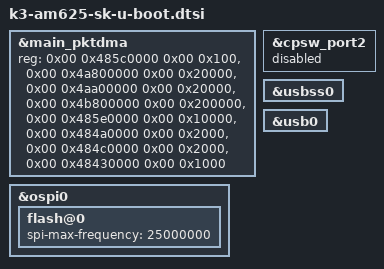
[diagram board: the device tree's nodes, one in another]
// SPDX-License-Identifier: GPL-2.0
/*
 * Common AM625 SK dts file for SPLs
 * Copyright (C) 2021-2022 Texas Instruments Incorporated - https://www.ti.com/
 */

#include "k3-am625-sk-binman.dtsi"
#include "k3-am625-u-boot.dtsi"

&main_pktdma {
	reg = <0x00 0x485c0000 0x00 0x100>,
	      <0x00 0x4a800000 0x00 0x20000>,
	      <0x00 0x4aa00000 0x00 0x20000>,
	      <0x00 0x4b800000 0x00 0x200000>,
	      <0x00 0x485e0000 0x00 0x10000>,
	      <0x00 0x484a0000 0x00 0x2000>,
	      <0x00 0x484c0000 0x00 0x2000>,
	      <0x00 0x48430000 0x00 0x1000>;
	reg-names = "gcfg", "rchanrt", "tchanrt", "ringrt",
		    "cfg", "tchan", "rchan", "rflow";
	bootph-all;
};

&cpsw_port2 {
	status = "disabled";
};

&usbss0 {
	bootph-all;
};

&usb0 {
	bootph-all;
};

&ospi0 {
	flash@0 {
		spi-max-frequency = <25000000>;
	};
};
